# MB9BF52xT register map
File version: 1.0
CPU: 
Registers are 8-bit, read-write, reset 0x0 unless marked. A register's access mark holds for its fields unless they carry their own. Offsets are from the block's base; lines under a group give offsets from that group; [hi:lo] are bit positions; {n}, {i} and the like mark numbered series; 'fields as' and 'values as' point back to an identical list; <NAME> marks a mode.

## Memory map
0x40000000 FLASH_IF blocks up to offset 0xC — peripheral FLASH_IF
0x40000200 UNIQUE_ID size 0x4 — peripheral UNIQUE_ID
0x40010000 CRG size 0x1 — peripheral CRG
0x40011000 HWWDT size 0x4 — peripheral HWWDT
0x40012000 SWWDT size 0x4 — peripheral SWWDT
0x40015000 DTIM size 0x1C — peripheral DTIM
0x40020000 MFT0 size 0x2 — peripheral MFT0
0x40024000 MFT_PPG size 0x2 — peripheral MFT_PPG
0x40025000 BT0 size 0x2 — peripheral BT0
0x40025040 BT1 size 0x2 — peripheral BT0
0x40025080 BT2 size 0x2 — peripheral BT0
0x400250C0 BT3 size 0x2 — peripheral BT0
0x40025100 BTIOSEL03 size 0x2 — peripheral BTIOSEL03
0x40025200 BT4 size 0x2 — peripheral BT0
0x40025240 BT5 size 0x2 — peripheral BT0
0x40025280 BT6 size 0x2 — peripheral BT0
0x400252C0 BT7 size 0x2 — peripheral BT0
0x40025300 BTIOSEL47 size 0x2 — peripheral BTIOSEL47
0x40025400 BT8 size 0x2 — peripheral BT0
0x40025440 BT9 size 0x2 — peripheral BT0
0x40025480 BT10 size 0x2 — peripheral BT0
0x400254C0 BT11 size 0x2 — peripheral BT0
0x40025500 BTIOSEL8B size 0x2 — peripheral BTIOSEL8B
0x40025600 BT12 size 0x2 — peripheral BT0
0x40025640 BT13 size 0x2 — peripheral BT0
0x40025680 BT14 size 0x2 — peripheral BT0
0x400256C0 BT15 size 0x2 — peripheral BT0
0x40025700 BTIOSELCF size 0x2 — peripheral BTIOSELCF
0x40025F00 SBSSR blocks up to offset 0xFE — peripheral SBSSR
0x40026000 QPRC0 size 0x2 — peripheral QPRC0
0x40026040 QPRC1 size 0x2 — peripheral QPRC0
0x40027000 ADC0 size 0x2 — peripheral ADC0
0x40027100 ADC1 size 0x2 — peripheral ADC0
0x40028000 DAC size 0x3 — peripheral DAC
0x4002E000 CRTRIM size 0x1 — peripheral CRTRIM
0x40030000 EXTI size 0x4 — peripheral EXTI
0x40031000 INTREQ size 0x4 — peripheral INTREQ
0x40033000 GPIO size 0x740 — peripheral GPIO
0x40034000 HDMICEC0 size 0x1 — peripheral HDMICEC0
0x40034100 HDMICEC1 size 0x1 — peripheral HDMICEC0
0x40035000 LVD size 0x2 — peripheral LVD
0x40035100 DS size 0x1 — peripheral DS
0x40036000 USBCLK size 0x1 — peripheral USBCLK
0x40037000 CANPRES size 0x1 — peripheral CANPRES
{0x40038000+0x100*n} MFS{n} size 0x2 (n=0..15) — peripheral MFS0
0x40039000 CRC size 0x1 — peripheral CRC
0x4003A000 WC size 0x3 — peripheral WC
0x4003B000 RTC size 0x13 — peripheral RTC
0x4003F000 EXBUS size 0x80 — peripheral EXBUS
0x40040000 USB0 blocks up to offset 0x2102 — peripheral USB0
0x40060000 DMAC size 0x4 — peripheral DMAC
0x40062000 CAN0 size 0xE — peripheral CAN0

## Interrupts
0 CSV (CRG)
1 SWDT (SWWDT)
2 LVD
3 WFG (MFT0)
4 EXTINT0_7 (EXTI)
5 EXTINT8_31 (EXTI)
6 DTIM_QDU (DTIM)
{2n+7} MFS{n}_{n+8}_RX (MFS{n}, MFS{n+8}) (n=0..7)
{2n+8} MFS{n}_{n+8}_TX (MFS{n}, MFS{n+8}) (n=0..7)
23 PPG (MFT_PPG)
24 OSC_PLL_WC_RTC (CRG)
25 ADC0
26 ADC1
28 FRTIM (MFT0)
29 INCAP (MFT0)
30 OUTCOMP (MFT0)
31 BTIM0_7 (BT{n} (n=0..15))
32 CAN0
34 USB0F (USB0)
35 USB0F_USB0H (USB0)
36 HDMICEC0
37 HDMICEC1
{n+38} DMAC{n} (DMAC) (n=0..7)

## FLASH_IF — peripheral FLASH_IF
Base 0x40000000
0x04 FRWTR 32-bit
  [1:0] RWT
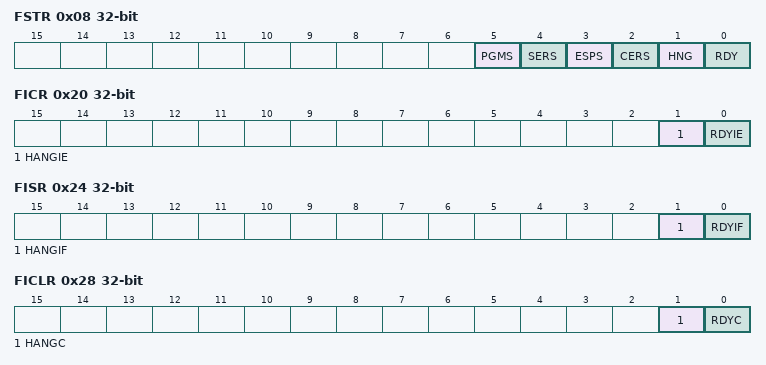
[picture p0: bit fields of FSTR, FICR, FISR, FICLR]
0x08 FSTR 32-bit ro
  [5] PGMS, [4] SERS, [3] ESPS, [2] CERS, [1] HNG, [0] RDY
0x20 FICR 32-bit
  [1] HANGIE, [0] RDYIE
0x24 FISR 32-bit
  [1] HANGIF, [0] RDYIF
0x28 FICLR 32-bit wo
  [1] HANGC rw, [0] RDYC rw
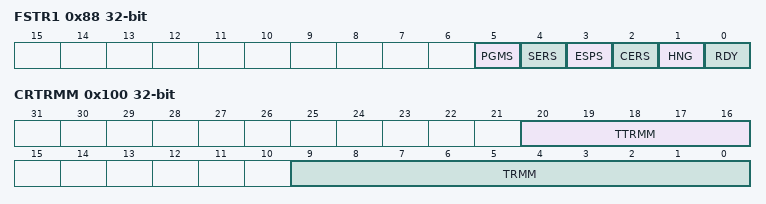
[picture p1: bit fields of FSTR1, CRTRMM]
0x88 FSTR1 32-bit
  [5] PGMS ro, [4] SERS ro, [3] ESPS ro, [2] CERS ro, [1] HNG ro, [0] RDY ro
0x100 CRTRMM 32-bit ro reset not defined
  [20:16] TTRMM, [9:0] TRMM

## UNIQUE_ID — peripheral UNIQUE_ID
Base 0x40000200
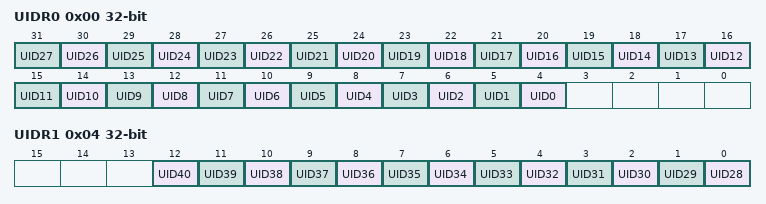
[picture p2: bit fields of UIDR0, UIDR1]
0x00 UIDR0 32-bit ro
  [n+4] UID{n} (n=0..27)
0x04 UIDR1 32-bit ro
  [n-28] UID{n} (n=28..40)

## CRG — peripheral CRG
Base 0x40010000
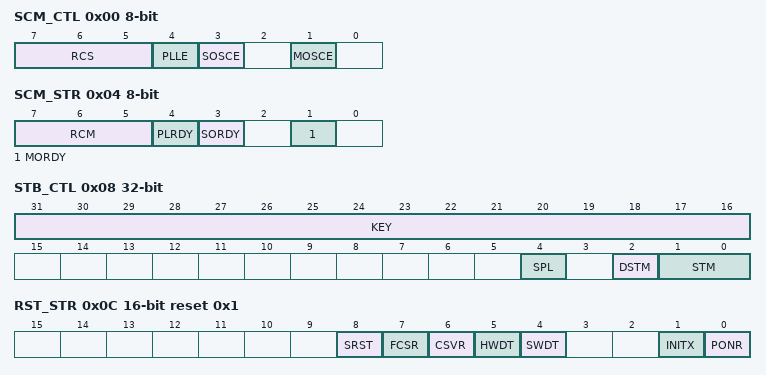
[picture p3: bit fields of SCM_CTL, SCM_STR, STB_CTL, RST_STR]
0x00 SCM_CTL
  [7:5] RCS, [4] PLLE, [3] SOSCE, [1] MOSCE
0x04 SCM_STR ro
  [7:5] RCM, [4] PLRDY, [3] SORDY, [1] MORDY
0x08 STB_CTL 32-bit
  [31:16] KEY, [4] SPL, [2] DSTM, [1:0] STM
0x0C RST_STR 16-bit ro reset 0x1
  [8] SRST, [7] FCSR, [6] CSVR, [5] HWDT, [4] SWDT, [1] INITX, [0] PONR
0x10 BSC_PSR
  [2:0] BSR
0x14 APBC0_PSR
  [1:0] APBC0
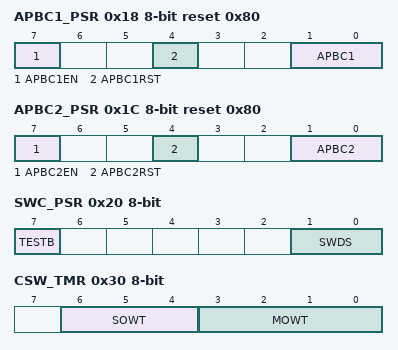
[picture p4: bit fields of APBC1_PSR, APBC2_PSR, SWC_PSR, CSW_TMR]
0x18 APBC1_PSR reset 0x80
  [7] APBC1EN, [4] APBC1RST, [1:0] APBC1
0x1C APBC2_PSR reset 0x80
  [7] APBC2EN, [4] APBC2RST, [1:0] APBC2
0x20 SWC_PSR (reset mask 0x3)
  [7] TESTB, [1:0] SWDS
0x28 TTC_PSR
  [1:0] TTC
0x30 CSW_TMR
  [6:4] SOWT, [3:0] MOWT
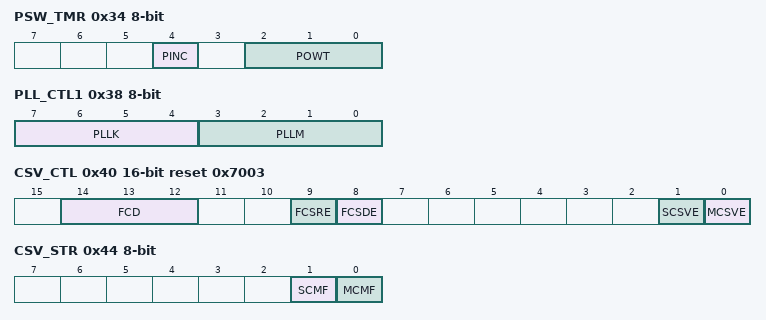
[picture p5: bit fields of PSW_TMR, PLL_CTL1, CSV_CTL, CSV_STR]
0x34 PSW_TMR
  [4] PINC, [2:0] POWT
0x38 PLL_CTL1
  [7:4] PLLK, [3:0] PLLM
0x3C PLL_CTL2
  [5:0] PLLN
0x40 CSV_CTL 16-bit reset 0x7003
  [14:12] FCD, [9] FCSRE, [8] FCSDE, [1] SCSVE, [0] MCSVE
0x44 CSV_STR ro
  [1] SCMF, [0] MCMF
0x48 FCSWH_CTL 16-bit reset 0xFFFF
0x4C FCSWL_CTL 16-bit
0x50 FCSWD_CTL 16-bit ro
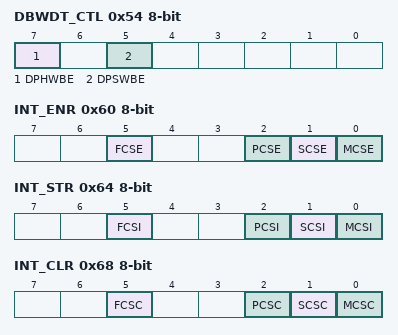
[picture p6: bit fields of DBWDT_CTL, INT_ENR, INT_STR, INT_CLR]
0x54 DBWDT_CTL
  [7] DPHWBE, [5] DPSWBE
0x60 INT_ENR
  [5] FCSE, [2] PCSE, [1] SCSE, [0] MCSE
0x64 INT_STR ro
  [5] FCSI, [2] PCSI, [1] SCSI, [0] MCSI
0x68 INT_CLR wo
  [5] FCSC, [2] PCSC, [1] SCSC, [0] MCSC
